# csi2_reva register map
Registers are 32-bit, access not given, no defined reset value unless marked. A register's access mark holds for its fields unless they carry their own. Offsets are from the block's base; lines under a group give offsets from that group; [hi:lo] are bit positions; {n}, {i} and the like mark numbered series; 'fields as' and 'values as' point back to an identical list; <NAME> marks a mode.

## Memory map
0x40062000 CSI2 size 0x1000 — Camera Serial Interface Registers.

## CSI2 — Camera Serial Interface Registers.
Base 0x40062000
0x00 CFG_NUM_LANES
  [3:0] LANES — Num Lanes for RX controller.
0x04 CFG_CLK_LANE_EN
  [0] EN — Enable lane clock setting for controller.
0x08 CFG_DATA_LANE_EN
  [7:0] EN — Enable data lane setting for controller.
0x0C CFG_FLUSH_COUNT
  [3:0] COUNT — Flush count setting for controller.
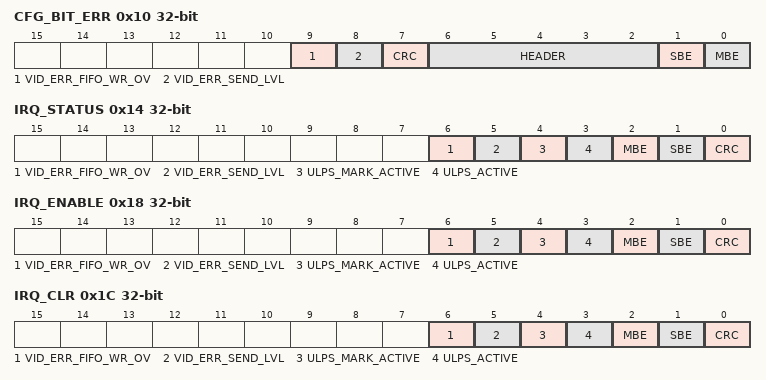
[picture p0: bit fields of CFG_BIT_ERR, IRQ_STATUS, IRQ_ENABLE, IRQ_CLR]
0x10 CFG_BIT_ERR
  [9] VID_ERR_FIFO_WR_OV — Video Error Fifo Overflow.
  [8] VID_ERR_SEND_LVL — Video Error Send Level.
  [7] CRC — CRC error.
  [6:2] HEADER — Header bit location of single bit ECC error.
  [1] SBE — Single bit ECC error.
  [0] MBE — Multiple bit ECC error.
0x14 IRQ_STATUS
  [6] VID_ERR_FIFO_WR_OV — Video Error Fifo Overflow.
  [5] VID_ERR_SEND_LVL — Video Error Send Level.
  [4] ULPS_MARK_ACTIVE — ULPS mark active status change.
  [3] ULPS_ACTIVE — ULPS active status change.
  [2] MBE — Multiple bit ECC error.
  [1] SBE — Single bit ECC error.
  [0] CRC — CRC error.
0x18 IRQ_ENABLE
  fields as IRQ_STATUS
0x1C IRQ_CLR
  fields as IRQ_STATUS
0x20 ULPS_CLK_STATUS
  [0] FIFO — FIFO Read/Write register.
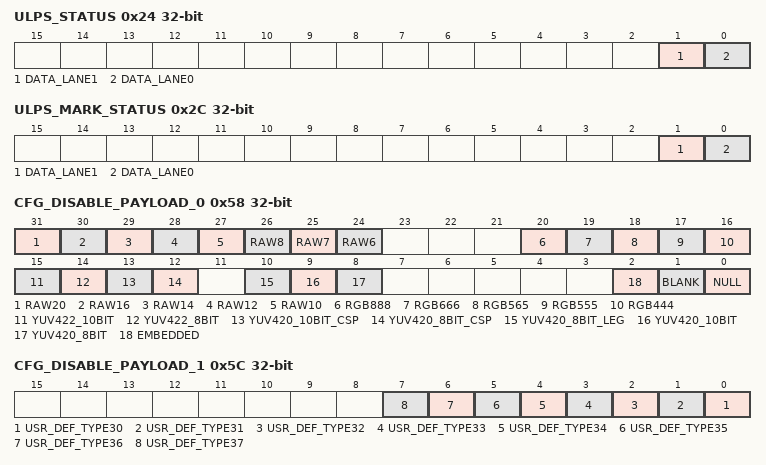
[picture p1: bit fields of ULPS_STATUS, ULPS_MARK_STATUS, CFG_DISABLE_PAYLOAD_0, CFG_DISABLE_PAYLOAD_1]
0x24 ULPS_STATUS
  [1] DATA_LANE1, [0] DATA_LANE0
0x28 ULPS_CLK_MARK_STATUS
  [0] CLK_LANE — Clock Lane.
0x2C ULPS_MARK_STATUS
  [1] DATA_LANE1, [0] DATA_LANE0
0x30 PPI_ERRSOT_HS
0x34 PPI_ERRSOTSYNC_HS
0x38 PPI_ERRESC
0x3C PPI_ERRSYNCESC
0x40 PPI_ERRCONTROL
0x44 CFG_CPHY_EN
0x48 CFG_PPI_16_EN
0x4C CFG_PACKET_INTERFACE_EN
0x50 CFG_VCX_EN
0x54 CFG_BYTE_DATA_FORMAT
0x58 CFG_DISABLE_PAYLOAD_0
  [31] RAW20, [30] RAW16, [29] RAW14, [28] RAW12, [27] RAW10, [26] RAW8, [25] RAW7, [24] RAW6, [20] RGB888, [19] RGB666, [18] RGB565, [17] RGB555, [16] RGB444, [15] YUV422_10BIT, [14] YUV422_8BIT, [13] YUV420_10BIT_CSP, [12] YUV420_8BIT_CSP, [10] YUV420_8BIT_LEG, [9] YUV420_10BIT, [8] YUV420_8BIT, [2] EMBEDDED, [1] BLANK, [0] NULL
0x5C CFG_DISABLE_PAYLOAD_1
  [n-30] USR_DEF_TYPE{n} (n=30..37) — User defined type {0x12+n}.
0x80 CFG_VID_IGNORE_VC
0x84 CFG_VID_VC
0x88 CFG_P_FIFO_SEND_LEVEL
0x8C CFG_VID_VSYNC
0x90 CFG_VID_HSYNC_FP
0x94 CFG_VID_HSYNC
0x98 CFG_VID_HSYNC_BP
0x400 CFG_DATABUS16_SEL
  [0] EN — Enable 16-bit data bus.
{0x404+4i} CFG_D{i}_SWAP_SEL (i=0..3)
  [2:0] SRC — Control Source.
    {v}=PAD_CDRX_L{v} (v=0..4)
0x414 CFG_C0_SWAP_SEL
  [2:0] SRC — Control Source.
    {v}=PAD_CDRX_L{v} (v=0..4)
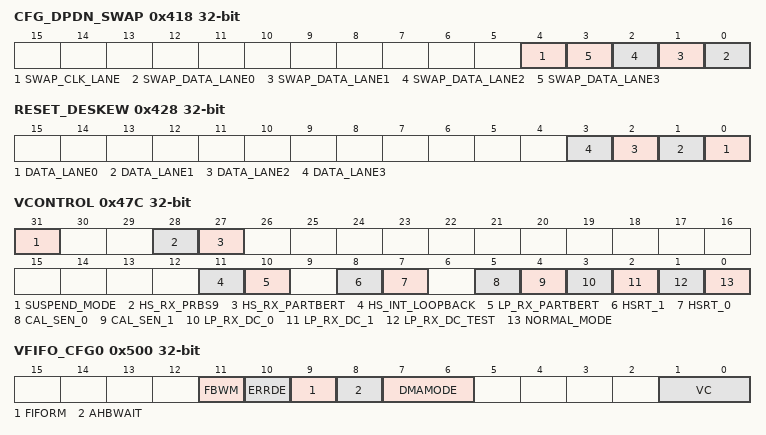
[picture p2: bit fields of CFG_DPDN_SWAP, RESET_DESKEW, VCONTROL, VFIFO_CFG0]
0x418 CFG_DPDN_SWAP
  [4] SWAP_CLK_LANE, [n] SWAP_DATA_LANE{n} (n=0..3)
0x41C RG_CFGCLK_1US_CNT
0x420 RG_HSRX_CLK_PRE_TIME_GRP0
0x424 RG_HSRX_DATA_PRE_TIME_GRP0
0x428 RESET_DESKEW
  [n] DATA_LANE{n} (n=0..3)
0x42C PMA_RDY
{0x430+4i} XCFGI_DW{i:02} (i=0..9)
0x458 XCFGI_DW0A
0x45C XCFGI_DW0B
0x460 XCFGI_DW0C
0x464 XCFGI_DW0D
0x468 GPIO_MODE
0x46C GPIO_DP_IE
0x470 GPIO_DN_IE
0x474 GPIO_DP_C
0x478 GPIO_DN_C
0x47C VCONTROL — PMA_RDY.
  [31] SUSPEND_MODE, [28] HS_RX_PRBS9, [27] HS_RX_PARTBERT, [11] HS_INT_LOOPBACK, [10] LP_RX_PARTBERT, [8] HSRT_1, [7] HSRT_0, [5] CAL_SEN_0, [4] CAL_SEN_1, [3] LP_RX_DC_0, [2] LP_RX_DC_1, [1] LP_RX_DC_TEST, [0] NORMAL_MODE
{0x47C+4i} MPSOV{i} (i=1..3)
0x490 RG_CDRX_DSIRX_EN
  [0] RXMODE
    0=CSI (CSI RX Mode.); 1=DSI (DSI RX Mode.)
0x494 RG_CDRX_L012_SUBLVDS_EN
0x498 RG_CDRX_L012_HSRT_CTRL
0x49C RG_CDRX_BISTHS_PLL_EN
0x4A0 RG_CDRX_BISTHS_PLL_PRE_DIV2
  [0] RXMODE
    0=CSI (CSI RX Mode.); 1=DSI (DSI RX Mode.)
0x4A4 RG_CDRX_BISTHS_PLL_FBK_INT
0x4A8 DBG1_MUX_SEL
0x4AC DBG2_MUX_SEL
0x4B0 DBG1_MUX_DOUT
0x4B4 DBG2_MUX_DOUT
0x4B8 AON_POWER_READY_N
0x4BC DPHY_RST_N
0x4C0 RXBYTECLKHS_INV
0x500 VFIFO_CFG0 — Video FIFO Configuration Register 0.
  [11] FBWM — Full Band Width mode.
  [10] ERRDE — Error Detection Enable.
  [9] FIFORM — FIFO Read Mode.
  [8] AHBWAIT — AHB Wait Enable.
  [7:6] DMAMODE — DMA Mode, the condition to trigger DMA request..
    0=NO_DMA; 1=DMA_REQ (Immediately send DMA request.); 2=FIFO_THD (Wait for FIFO above threshold.); 3=FIFO_FULL (Wait for FIFO is full.)
  [1:0] VC — CSI Virtual Channel.
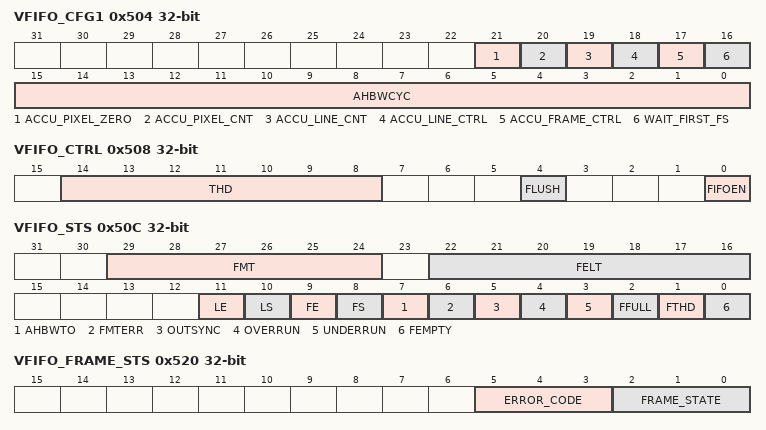
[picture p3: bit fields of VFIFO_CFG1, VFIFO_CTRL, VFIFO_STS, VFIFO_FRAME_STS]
0x504 VFIFO_CFG1 — Video FIFO Configuration Register 1.
  [21] ACCU_PIXEL_ZERO
  [20] ACCU_PIXEL_CNT
  [19] ACCU_LINE_CNT
  [18] ACCU_LINE_CTRL
  [17] ACCU_FRAME_CTRL
  [16] WAIT_FIRST_FS
  [15:0] AHBWCYC — Maximal AHB Wait Clock Cycles.
0x508 VFIFO_CTRL — Video FIFO Control Register.
  [14:8] THD — FIFO Threshold.
  [4] FLUSH — Write 1 to flush FIFO contents.
  [0] FIFOEN — Video FIFO Enable.
    0=DIS (Disable.); 1=EN (Enable.)
0x50C VFIFO_STS — Video FIFO Status Register.
  [29:24] FMT — CSI pixel format of current transaction
  [22:16] FELT — FIFO remaining entity count
  [11] LE — CSI Line End
  [10] LS — CSI Line Start
  [9] FE — CSI Frame End
  [8] FS — CSI Frame Start
  [7] AHBWTO — AHB wait time out
  [6] FMTERR — CSI Pixel Format Error
  [5] OUTSYNC — CSI out of sync
  [4] OVERRUN — FIFO overrun
  [3] UNDERRUN — FIFO underrun
  [2] FFULL — FIFO full.
  [1] FTHD — FIFO above threshold.
  [0] FEMPTY — FIFO empty.
0x510 VFIFO_LINE_NUM — Video FIFO CSI Line Number Per Frame.
  [12:0] LINE_NUM — Number of lines per frame.
0x514 VFIFO_PIXEL_NUM — Video FIFO CSI Pixel Number Per Line.
  [13:0] PIXEL_NUM — Number of pixels per line.
0x518 VFIFO_LINE_CNT — Video FIFO CSI Line Count.
  [11:0] LINE_CNT — Number of received lines in current frame.
0x51C VFIFO_PIXEL_CNT — Video FIFO CSI Pixel Count.
  [12:0] PIXEL_CNT — Number of received pixels in current line in a frame.
0x520 VFIFO_FRAME_STS — Video FIFO Frame Status Register.
  [5:3] ERROR_CODE — Error Codes.
  [2:0] FRAME_STATE
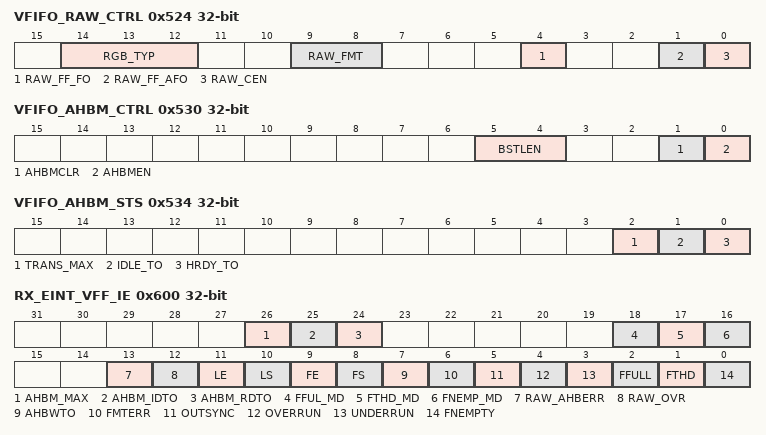
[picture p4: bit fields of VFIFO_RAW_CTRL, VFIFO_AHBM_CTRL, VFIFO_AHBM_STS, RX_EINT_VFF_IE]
0x524 VFIFO_RAW_CTRL — Video FIFO RAW-to-RGB Control Register.
  [14:12] RGB_TYP — RGB type.
    0=RGB444; 1=RGB555; 2=RGB565; 3=RGB666; 4=RGG888
  [9:8] RAW_FMT — RAW format.
    0=RGRG_GBGB; 1=GRGR_BGBG; 2=GBGB_RGRG; 3=BGBG_GRGR
  [4] RAW_FF_FO — RAW conversion FIFO flush-out trigger.
  [1] RAW_FF_AFO — RAW conversion FIFO automatic flush-out.
  [0] RAW_CEN — RAW conversion enable.
0x528 VFIFO_RAW_BUF0_ADDR — Video FIFO RAW-to-RGB Line Buffer0 Address.
  [31:2] ADDR — RAM address for RAW conversion buffer 0, word-aligned.
0x52C VFIFO_RAW_BUF1_ADDR — Video FIFO RAW-to-RGB Line Buffer1 Address.
  [31:2] ADDR — RAM address for RAW conversion buffer 1, word-aligned.
0x530 VFIFO_AHBM_CTRL — Video FIFO AHB Master Control Register.
  [5:4] BSTLEN — AHB Burst Length.
    0=VFIFO_THD (Video FIFO THD.); 1=ONE_WORD; 2=FOUR_WORDS; 3=EIGHT_WORDS
  [1] AHBMCLR — AHB Master Status Clear.
  [0] AHBMEN — AHB Master Enable.
0x534 VFIFO_AHBM_STS — Video FIFO AHB Master Status Register.
  [2] TRANS_MAX — AHB master maximal transfer count occurrence.
  [1] IDLE_TO — AHB master Idle time-out.
  [0] HRDY_TO — AHB master HREADY time-out.
0x538 VFIFO_AHBM_START_ADDR — Video FIFO AHB Master Start Address Register.
  [31:2] AHBM_START_ADDR — AHB master transfer starting address, word-aligned.
0x53C VFIFO_AHBM_ADDR_RANGE — Video FIFO AHB Master Address Range Register.
  [15:2] AHBM_ADDR_RANGE — AHB master address range.
0x540 VFIFO_AHBM_MAX_TRANS — Video FIFO AHB Master Maximal Transfer Number Register.
  [31:0] AHBM_MAX_TRANS — AHB master maximal number of transfer word count.
0x544 VFIFO_AHBM_TRANS_CNT — Video FIFO AHB Master Transfer Count Register.
  [31:0] AHBM_TRANS_CNT — AHB master number of words been transferred.
0x600 RX_EINT_VFF_IE — RX Video FIFO Interrupt Enable Register.
  [26] AHBM_MAX
  [25] AHBM_IDTO
  [24] AHBM_RDTO
  [18] FFUL_MD — Video FIFO full detection mode
  [17] FTHD_MD — Video FIFO threshold detection mode
  [16] FNEMP_MD — Video FIFO not empty detection mode
  [13] RAW_AHBERR — Raw AHB Error Interrupt Enable
  [12] RAW_OVR — Raw FIFO Overrun Interrupt Enable
  [11] LE — CSI Line End interrupt enable
  [10] LS — CSI Line Start interrupt enable
  [9] FE — CSI Frame End interrupt enable
  [8] FS — CSI Frame Start interrupt enable
  [7] AHBWTO — AHB wait time out interrupt enable
  [6] FMTERR — CSI Pixel Format Error interrupt enable
  [5] OUTSYNC — CSI out of sync interrupt enable
  [4] OVERRUN — Video FIFO overrun interrupt enable
  [3] UNDERRUN — Video FIFO underrun interrupt enable
  [2] FFULL — Video FIFO full interrupt enable.
  [1] FTHD — Video FIFO above threshold interrupt enable.
  [0] FNEMPTY — Video FIFO not empty interrupt enable.
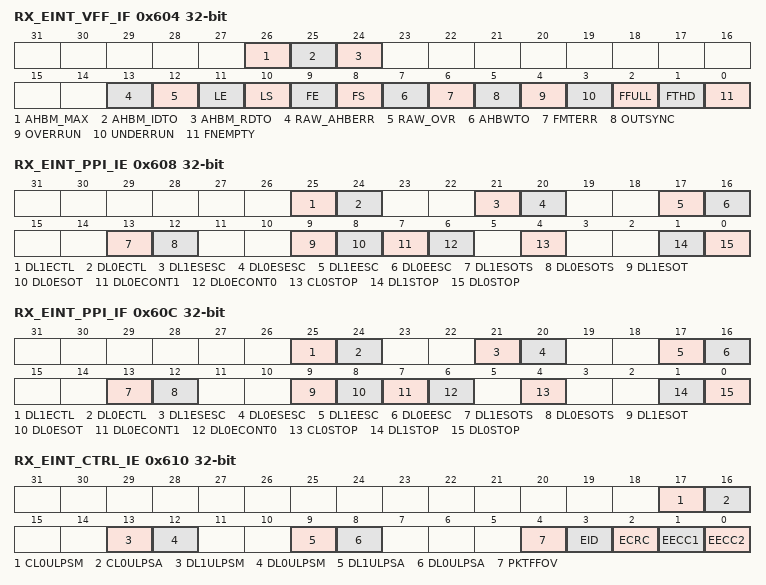
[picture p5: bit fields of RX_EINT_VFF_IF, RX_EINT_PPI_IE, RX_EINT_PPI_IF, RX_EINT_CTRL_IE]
0x604 RX_EINT_VFF_IF — RX Video FIFO Interrupt Flag Register.
  [26] AHBM_MAX
  [25] AHBM_IDTO
  [24] AHBM_RDTO
  [13] RAW_AHBERR — Raw AHB Error Interrupt Enable
  [12] RAW_OVR — Raw FIFO Overrun Interrupt Enable
  [11] LE — CSI Line End interrupt flag
  [10] LS — CSI Line Start interrupt flag
  [9] FE — CSI Frame End interrupt flag
  [8] FS — CSI Frame Start interrupt flag
  [7] AHBWTO — AHB wait time out interrupt flag
  [6] FMTERR — CSI Pixel Format Error interrupt flag
  [5] OUTSYNC — CSI out of sync interrupt flag
  [4] OVERRUN — Video FIFO overrun interrupt flag
  [3] UNDERRUN — Video FIFO underrun interrupt flag
  [2] FFULL — Video FIFO full interrupt flag.
  [1] FTHD — Video FIFO above threshold interrupt flag.
  [0] FNEMPTY — Video FIFO not empty interrupt flag.
0x608 RX_EINT_PPI_IE — RX D-PHY Interrupt Enable Register.
  [25] DL1ECTL — DPHY Data Lane1 Control Error (ppi_errcontrol_lan0) interrupt enable
  [24] DL0ECTL — DPHY Data Lane0 Control Error (ppi_errcontrol_lan0) interrupt enable
  [21] DL1ESESC — DPHY Data Lane1 Low-Power Data Transmission Synchronization Error (ppi_errsyncesc_lan0) interrupt enable
  [20] DL0ESESC — DPHY Data Lane0 Low-Power Data Transmission Synchronization Error (ppi_errsyncesc_lan0) interrupt enable
  [17] DL1EESC — DPHY Data Lane1 Escape Entry Error (ppi_erresc_lan1) interrupt enable
  [16] DL0EESC — DPHY Data Lane0 Escape Entry Error (ppi_erresc_lan0) interrupt enable
  [13] DL1ESOTS — DPHY Data Lane1 SOT Synchronization Error (ppi_errsotsynchs_lan1) interrupt enable
  [12] DL0ESOTS — DPHY Data Lane0 SOT Synchronization Error (ppi_errsotsynchs_lan0) interrupt enable
  [9] DL1ESOT — DPHY Data Lane1 Start-of-Transmission (SoT) Error (ppi_errsoths_lan1) interrupt enable
  [8] DL0ESOT — DPHY Data Lane0 Start-of-Transmission (SoT) Error (ppi_errsoths_lan0) interrupt enable
  [7] DL0ECONT1 — DPHY Data Lane0 LP1 Contention Error (ppi_errcontentionp1_lan0) interrupt enable
  [6] DL0ECONT0 — DPHY Data Lane0 LP0 Contention Error (ppi_errcontentionp0_lan0) interrupt enable
  [4] CL0STOP — DPHY Clock Lane0 Stop State (ppi_stopstate_clk0) interrupt enable.
  [1] DL1STOP — DPHY Data Lane1 Stop State (ppi_stopstate_lan1) interrupt enable.
  [0] DL0STOP — DPHY Data Lane0 Stop State (ppi_stopstate_lan0) interrupt enable.
0x60C RX_EINT_PPI_IF — RX D-PHY Interrupt Flag Register.
  [25] DL1ECTL — DPHY Data Lane1 Control Error (ppi_errcontrol_lan0) interrupt flag
  [24] DL0ECTL — DPHY Data Lane0 Control Error (ppi_errcontrol_lan0) interrupt flag
  [21] DL1ESESC — DPHY Data Lane1 Low-Power Data Transmission Synchronization Error (ppi_errsyncesc_lan0) interrupt flag
  [20] DL0ESESC — DPHY Data Lane0 Low-Power Data Transmission Synchronization Error (ppi_errsyncesc_lan0) interrupt flag
  [17] DL1EESC — DPHY Data Lane1 Escape Entry Error (ppi_erresc_lan1) interrupt flag
  [16] DL0EESC — DPHY Data Lane0 Escape Entry Error (ppi_erresc_lan0) interrupt flag
  [13] DL1ESOTS — DPHY Data Lane1 SOT Synchronization Error (ppi_errsotsynchs_lan1) interrupt flag
  [12] DL0ESOTS — DPHY Data Lane0 SOT Synchronization Error (ppi_errsotsynchs_lan0) interrupt flag
  [9] DL1ESOT — DPHY Data Lane1 Start-of-Transmission (SoT) Error (ppi_errsoths_lan1) interrupt flag
  [8] DL0ESOT — DPHY Data Lane0 Start-of-Transmission (SoT) Error (ppi_errsoths_lan0) interrupt flag
  [7] DL0ECONT1 — DPHY Data Lane0 LP1 Contention Error (ppi_errcontentionp1_lan0) interrupt flag
  [6] DL0ECONT0 — DPHY Data Lane0 LP0 Contention Error (ppi_errcontentionp0_lan0) interrupt flag
  [4] CL0STOP — DPHY Clock Lane0 Stop State (ppi_stopstate_clk0) interrupt flag.
  [1] DL1STOP — DPHY Data Lane1 Stop State (ppi_stopstate_lan1) interrupt flag.
  [0] DL0STOP — DPHY Data Lane0 Stop State (ppi_stopstate_lan0) interrupt flag.
0x610 RX_EINT_CTRL_IE — RX Controller Interrupt Enable Register.
  [17] CL0ULPSM — CSI Data Lane0 ULPSS Mark interrupt enable
  [16] CL0ULPSA — CSI Clock Lane0 ULPSS Active interrupt enable
  [13] DL1ULPSM — CSI Data Lane1 ULPSS Mark interrupt enable
  [12] DL0ULPSM — CSI Data Lane0 ULPSS Mark interrupt enable
  [9] DL1ULPSA — CSI Data Lane1 ULPSS Active interrupt enable
  [8] DL0ULPSA — CSI Data Lane0 ULPSS Active interrupt enable
  [4] PKTFFOV — CSI RX Packet FIFO Overrun interrupt enable
  [3] EID — CSI RX Packet Header Data ID Error interrupt enable
  [2] ECRC — CSI RX CRC Error interrupt enable.
  [1] EECC1 — CSI RX ECC 1-bit Error interrupt enable.
  [0] EECC2 — CSI RX ECC 2-bit Error interrupt enable.
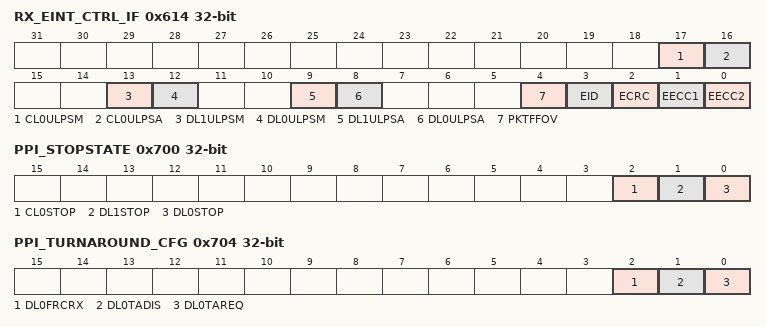
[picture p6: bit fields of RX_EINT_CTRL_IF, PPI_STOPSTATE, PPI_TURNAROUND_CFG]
0x614 RX_EINT_CTRL_IF — RX Controller Interrupt Flag Register.
  [17] CL0ULPSM — CSI Data Lane0 ULPSS Mark interrupt flag
  [16] CL0ULPSA — CSI Clock Lane0 ULPSS Active interrupt flag
  [13] DL1ULPSM — CSI Data Lane1 ULPSS Mark interrupt flag
  [12] DL0ULPSM — CSI Data Lane0 ULPSS Mark interrupt flag
  [9] DL1ULPSA — CSI Data Lane1 ULPSS Active interrupt flag
  [8] DL0ULPSA — CSI Data Lane0 ULPSS Active interrupt flag
  [4] PKTFFOV — CSI RX Packet FIFO Overrun interrupt flag
  [3] EID — CSI RX Packet Header Data ID Error interrupt flag
  [2] ECRC — CSI RX CRC Error interrupt flag.
  [1] EECC1 — CSI RX ECC 1-bit Error interrupt flag.
  [0] EECC2 — CSI RX ECC 2-bit Error interrupt flag.
0x700 PPI_STOPSTATE — DPHY PPI Stop State Register.
  [2] CL0STOP — CSI Clock Lane0 Stop State.
  [1] DL1STOP — CSI Data Lane1 Stop State.
  [0] DL0STOP — CSI Data Lane0 Stop State.
0x704 PPI_TURNAROUND_CFG — DPHY PPI Turn-Around Configuration Register.
  [2] DL0FRCRX — CSI Data Lane0 force RX mode.
  [1] DL0TADIS — CSI Data Lane0 turn around disable.
  [0] DL0TAREQ — CSI Data Lane0 turn around request.
